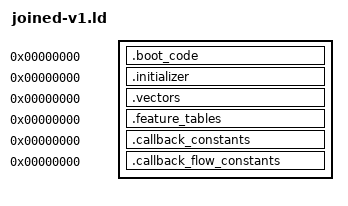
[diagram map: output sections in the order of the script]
OUTPUT_ARCH(riscv)
SECTIONS
{
 .boot_code 0 : SUBALIGN(2) { *(.boot_code)
  *(.text.tsl9_callback_flow_external_d1a8)
  *(.text.tsl9_callback_flow_external_16dac)
  *(.text.tsl9_callback_support_block_16dba)
  *(.text.tsl9_callback_support_block_16dcc)
  *(.text.tsl9_callback_support_block_16dd2)
 }
 .initializer 0 : SUBALIGN(4) { *(.initializer) }
 .vectors 0 : SUBALIGN(4) { *(.vectors) }
 .feature_tables 0 : SUBALIGN(4) { *(.feature_tables) }
 .callback_constants 0 : SUBALIGN(4) { *(.callback_constants) }
 .callback_flow_constants 0 : SUBALIGN(4) { *(.callback_flow_constants) }
 /DISCARD/ : { *(.comment) *(.riscv.attributes) *(.llvm_addrsig) }
}
